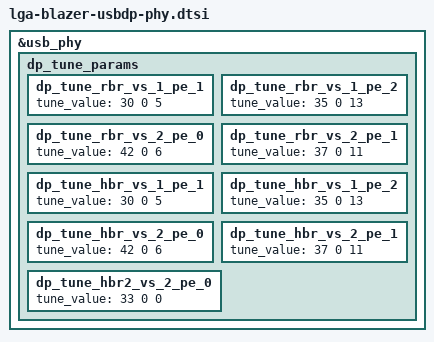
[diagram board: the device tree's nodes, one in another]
// SPDX-License-Identifier: GPL-2.0-only
/*
 * Blazer USBDP PHY device tree
 *
 * Copyright 2025 Google LLC
 *
 */

&usb_phy {
	dp_tune_params {
		/* RBR */
		dp_tune_rbr_vs_1_pe_1 {
			tune_value = <30 0 5>;
		};
		dp_tune_rbr_vs_1_pe_2 {
			tune_value = <35 0 13>;
		};
		dp_tune_rbr_vs_2_pe_0 {
			tune_value = <42 0 6>;
		};
		dp_tune_rbr_vs_2_pe_1 {
			tune_value = <37 0 11>;
		};
		/* HBR */
		dp_tune_hbr_vs_1_pe_1 {
			tune_value = <30 0 5>;
		};
		dp_tune_hbr_vs_1_pe_2 {
			tune_value = <35 0 13>;
		};
		dp_tune_hbr_vs_2_pe_0 {
			tune_value = <42 0 6>;
		};
		dp_tune_hbr_vs_2_pe_1 {
			tune_value = <37 0 11>;
		};
		/* HBR2 */
		dp_tune_hbr2_vs_2_pe_0 {
			tune_value = <33 0 0>;
		};
	};
};
